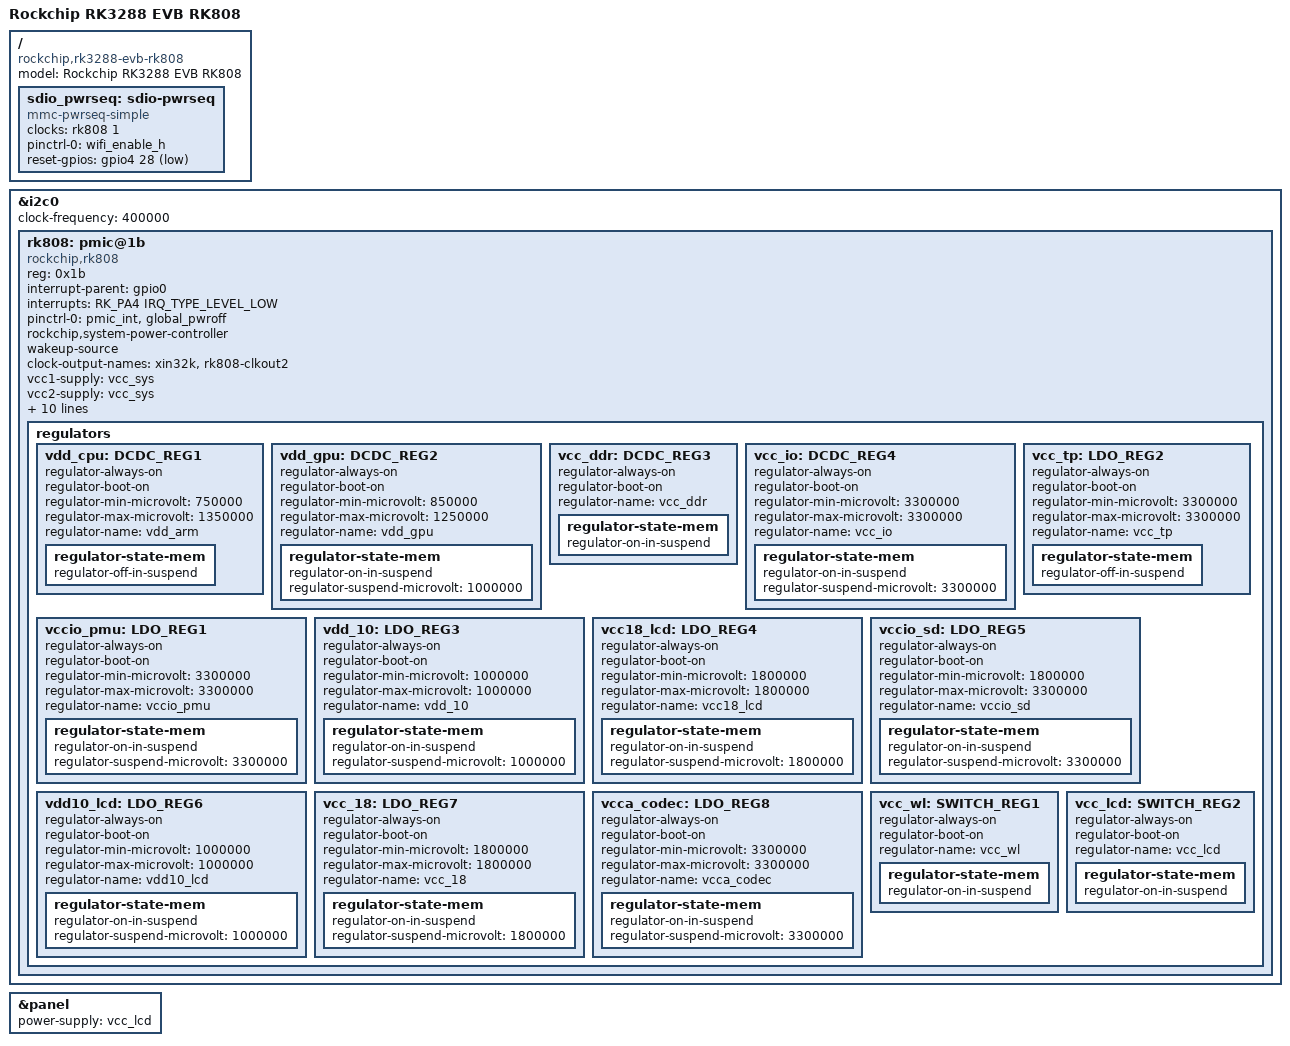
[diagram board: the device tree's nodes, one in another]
// SPDX-License-Identifier: (GPL-2.0+ OR MIT)

/dts-v1/;
#include "rk3288-evb.dtsi"

/ {
	model = "Rockchip RK3288 EVB RK808";
	compatible = "rockchip,rk3288-evb-rk808", "rockchip,rk3288";

	sdio_pwrseq: sdio-pwrseq {
		compatible = "mmc-pwrseq-simple";
		clocks = <&rk808 1>;
		clock-names = "ext_clock";
		pinctrl-names = "default";
		pinctrl-0 = <&wifi_enable_h>;

		/*
		 * On the module itself this is one of these (depending
		 * on the actual card populated):
		 * - SDIO_RESET_L_WL_REG_ON
		 * - PDN (power down when low)
		 */
		reset-gpios = <&gpio4 28 GPIO_ACTIVE_LOW>;
	};
};

&i2c0 {
	clock-frequency = <400000>;

	rk808: pmic@1b {
		compatible = "rockchip,rk808";
		reg = <0x1b>;
		interrupt-parent = <&gpio0>;
		interrupts = <RK_PA4 IRQ_TYPE_LEVEL_LOW>;
		pinctrl-names = "default";
		pinctrl-0 = <&pmic_int &global_pwroff>;
		rockchip,system-power-controller;
		wakeup-source;
		#clock-cells = <1>;
		clock-output-names = "xin32k", "rk808-clkout2";

		vcc1-supply = <&vcc_sys>;
		vcc2-supply = <&vcc_sys>;
		vcc3-supply = <&vcc_sys>;
		vcc4-supply = <&vcc_sys>;
		vcc6-supply = <&vcc_sys>;
		vcc7-supply = <&vcc_sys>;
		vcc8-supply = <&vcc_18>;
		vcc9-supply = <&vcc_io>;
		vcc10-supply = <&vcc_io>;
		vcc11-supply = <&vcc_sys>;
		vcc12-supply = <&vcc_io>;
		vddio-supply = <&vccio_pmu>;

		regulators {
			vdd_cpu: DCDC_REG1 {
				regulator-always-on;
				regulator-boot-on;
				regulator-min-microvolt = <750000>;
				regulator-max-microvolt = <1350000>;
				regulator-name = "vdd_arm";
				regulator-state-mem {
					regulator-off-in-suspend;
				};
			};

			vdd_gpu: DCDC_REG2 {
				regulator-always-on;
				regulator-boot-on;
				regulator-min-microvolt = <850000>;
				regulator-max-microvolt = <1250000>;
				regulator-name = "vdd_gpu";
				regulator-state-mem {
					regulator-on-in-suspend;
					regulator-suspend-microvolt = <1000000>;
				};
			};

			vcc_ddr: DCDC_REG3 {
				regulator-always-on;
				regulator-boot-on;
				regulator-name = "vcc_ddr";
				regulator-state-mem {
					regulator-on-in-suspend;
				};
			};

			vcc_io: DCDC_REG4 {
				regulator-always-on;
				regulator-boot-on;
				regulator-min-microvolt = <3300000>;
				regulator-max-microvolt = <3300000>;
				regulator-name = "vcc_io";
				regulator-state-mem {
					regulator-on-in-suspend;
					regulator-suspend-microvolt = <3300000>;
				};
			};

			vccio_pmu: LDO_REG1 {
				regulator-always-on;
				regulator-boot-on;
				regulator-min-microvolt = <3300000>;
				regulator-max-microvolt = <3300000>;
				regulator-name = "vccio_pmu";
				regulator-state-mem {
					regulator-on-in-suspend;
					regulator-suspend-microvolt = <3300000>;
				};
			};

			vcc_tp: LDO_REG2 {
				regulator-always-on;
				regulator-boot-on;
				regulator-min-microvolt = <3300000>;
				regulator-max-microvolt = <3300000>;
				regulator-name = "vcc_tp";
				regulator-state-mem {
					regulator-off-in-suspend;
				};
			};

			vdd_10: LDO_REG3 {
				regulator-always-on;
				regulator-boot-on;
				regulator-min-microvolt = <1000000>;
				regulator-max-microvolt = <1000000>;
				regulator-name = "vdd_10";
				regulator-state-mem {
					regulator-on-in-suspend;
					regulator-suspend-microvolt = <1000000>;
				};
			};

			vcc18_lcd: LDO_REG4 {
				regulator-always-on;
				regulator-boot-on;
				regulator-min-microvolt = <1800000>;
				regulator-max-microvolt = <1800000>;
				regulator-name = "vcc18_lcd";
				regulator-state-mem {
					regulator-on-in-suspend;
					regulator-suspend-microvolt = <1800000>;
				};
			};

			vccio_sd: LDO_REG5 {
				regulator-always-on;
				regulator-boot-on;
				regulator-min-microvolt = <1800000>;
				regulator-max-microvolt = <3300000>;
				regulator-name = "vccio_sd";
				regulator-state-mem {
					regulator-on-in-suspend;
					regulator-suspend-microvolt = <3300000>;
				};
			};

			vdd10_lcd: LDO_REG6 {
				regulator-always-on;
				regulator-boot-on;
				regulator-min-microvolt = <1000000>;
				regulator-max-microvolt = <1000000>;
				regulator-name = "vdd10_lcd";
				regulator-state-mem {
					regulator-on-in-suspend;
					regulator-suspend-microvolt = <1000000>;
				};
			};

			vcc_18: LDO_REG7 {
				regulator-always-on;
				regulator-boot-on;
				regulator-min-microvolt = <1800000>;
				regulator-max-microvolt = <1800000>;
				regulator-name = "vcc_18";
				regulator-state-mem {
					regulator-on-in-suspend;
					regulator-suspend-microvolt = <1800000>;
				};
			};

			vcca_codec: LDO_REG8 {
				regulator-always-on;
				regulator-boot-on;
				regulator-min-microvolt = <3300000>;
				regulator-max-microvolt = <3300000>;
				regulator-name = "vcca_codec";
				regulator-state-mem {
					regulator-on-in-suspend;
					regulator-suspend-microvolt = <3300000>;
				};
			};

			vcc_wl: SWITCH_REG1 {
				regulator-always-on;
				regulator-boot-on;
				regulator-name = "vcc_wl";
				regulator-state-mem {
					regulator-on-in-suspend;
				};
			};

			vcc_lcd: SWITCH_REG2 {
				regulator-always-on;
				regulator-boot-on;
				regulator-name = "vcc_lcd";
				regulator-state-mem {
					regulator-on-in-suspend;
				};
			};
		};
	};
};

&panel {
	power-supply = <&vcc_lcd>;
};
